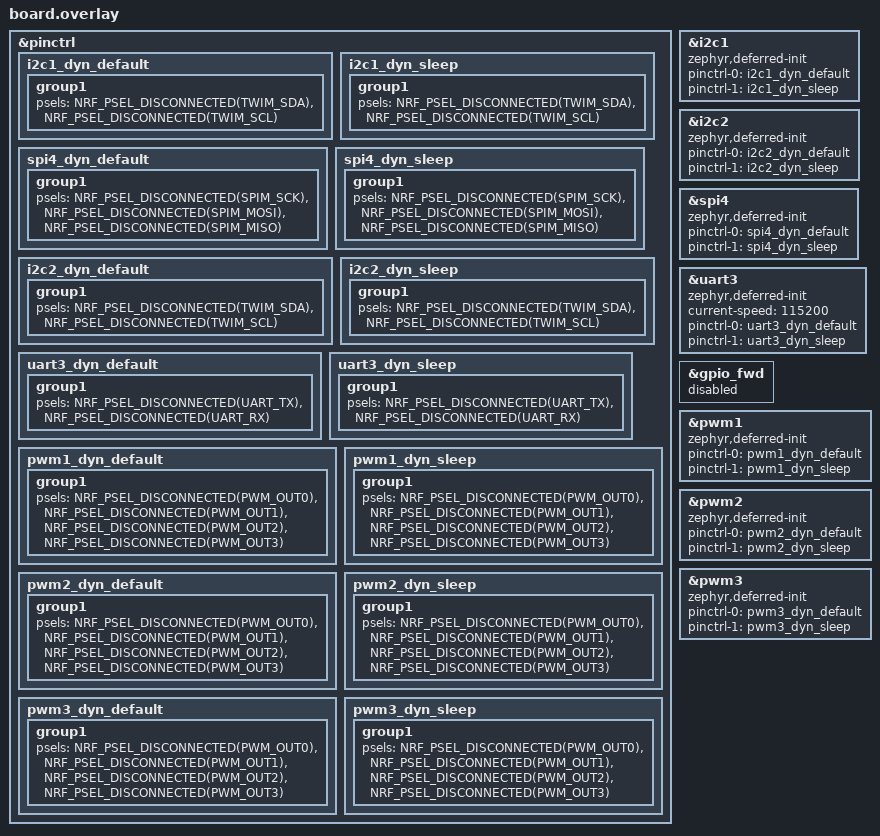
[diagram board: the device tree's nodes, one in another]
// TODO: restore the I2S for the Open Music Labs Audio Codec Shield. The fixed
// i2s0 that was here used the Arduino SPI pins (D10-D13), so board.SPI() could
// not use them, and audiobusio.I2SOut can't be routed dynamically yet.

// Enable free serial peripheral instances so CircuitPython can mux them to
// arbitrary pins at runtime. Each instance is enabled in one mode because the
// i2c/spi/uart nodes of an instance are the same peripheral (enforced by
// zephyr/soc/nordic/validate_enabled_instances.c). All signals are
// disconnected and the devices are marked zephyr,deferred-init so nothing is
// claimed at boot; iobroker initializes and routes a device when a busio
// object is constructed and de-initializes it on release.
//
// See "nRF serial instances" in internal-modules/iobroker/README.md for how
// the instances are shared and allocated.
//
// Instance 0 is left alone: uart0 is the console and i2c0/spi0 share that
// same peripheral, so they must not be enabled. Instance 1 is i2c1, the
// Arduino header I2C. spi4 is the upstream Arduino header SPI and the only
// SPI instance. uart1 is the upstream Arduino serial, but it is the same
// instance as i2c1, so busio.UART uses uart3.

&pinctrl {
	i2c1_dyn_default: i2c1_dyn_default {
		group1 {
			psels = <NRF_PSEL_DISCONNECTED(TWIM_SDA)>,
				<NRF_PSEL_DISCONNECTED(TWIM_SCL)>;
		};
	};

	i2c1_dyn_sleep: i2c1_dyn_sleep {
		group1 {
			psels = <NRF_PSEL_DISCONNECTED(TWIM_SDA)>,
				<NRF_PSEL_DISCONNECTED(TWIM_SCL)>;
		};
	};

	spi4_dyn_default: spi4_dyn_default {
		group1 {
			psels = <NRF_PSEL_DISCONNECTED(SPIM_SCK)>,
				<NRF_PSEL_DISCONNECTED(SPIM_MOSI)>,
				<NRF_PSEL_DISCONNECTED(SPIM_MISO)>;
		};
	};

	spi4_dyn_sleep: spi4_dyn_sleep {
		group1 {
			psels = <NRF_PSEL_DISCONNECTED(SPIM_SCK)>,
				<NRF_PSEL_DISCONNECTED(SPIM_MOSI)>,
				<NRF_PSEL_DISCONNECTED(SPIM_MISO)>;
		};
	};

	i2c2_dyn_default: i2c2_dyn_default {
		group1 {
			psels = <NRF_PSEL_DISCONNECTED(TWIM_SDA)>,
				<NRF_PSEL_DISCONNECTED(TWIM_SCL)>;
		};
	};

	i2c2_dyn_sleep: i2c2_dyn_sleep {
		group1 {
			psels = <NRF_PSEL_DISCONNECTED(TWIM_SDA)>,
				<NRF_PSEL_DISCONNECTED(TWIM_SCL)>;
		};
	};

	uart3_dyn_default: uart3_dyn_default {
		group1 {
			psels = <NRF_PSEL_DISCONNECTED(UART_TX)>,
				<NRF_PSEL_DISCONNECTED(UART_RX)>;
		};
	};

	uart3_dyn_sleep: uart3_dyn_sleep {
		group1 {
			psels = <NRF_PSEL_DISCONNECTED(UART_TX)>,
				<NRF_PSEL_DISCONNECTED(UART_RX)>;
		};
	};
};

&i2c1 {
	status = "okay";
	zephyr,deferred-init;
	pinctrl-0 = <&i2c1_dyn_default>;
	pinctrl-1 = <&i2c1_dyn_sleep>;
	pinctrl-names = "default", "sleep";
};

&i2c2 {
	status = "okay";
	zephyr,deferred-init;
	pinctrl-0 = <&i2c2_dyn_default>;
	pinctrl-1 = <&i2c2_dyn_sleep>;
	pinctrl-names = "default", "sleep";
};

&spi4 {
	status = "okay";
	zephyr,deferred-init;
	pinctrl-0 = <&spi4_dyn_default>;
	pinctrl-1 = <&spi4_dyn_sleep>;
	pinctrl-names = "default", "sleep";
};

&uart3 {
	status = "okay";
	zephyr,deferred-init;
	current-speed = <115200>;
	pinctrl-0 = <&uart3_dyn_default>;
	pinctrl-1 = <&uart3_dyn_sleep>;
	pinctrl-names = "default", "sleep";
};

// The upstream board forwards the Arduino D0/D1 pins (P1.00/P1.01) and
// P0.10/P0.11 to the network core for its UART console, so the application
// core could not use them. Keep them on the application core, for
// board.UART() on TX/RX (D1/D0).
&gpio_fwd {
	status = "disabled";
};

// PWM instances 1-3, same scheme: all four outputs disconnected and deferred
// init, so iobroker can hand an instance to neopixel_write and pwmio and
// route its outputs at runtime. Instance 0 is left as the board defines it:
// enabled with fixed pins for the PWM LED. nRF5340 has no power-domain pin
// restrictions, so any instance can drive any pad.

&pinctrl {
	pwm1_dyn_default: pwm1_dyn_default {
		group1 {
			psels = <NRF_PSEL_DISCONNECTED(PWM_OUT0)>,
				<NRF_PSEL_DISCONNECTED(PWM_OUT1)>,
				<NRF_PSEL_DISCONNECTED(PWM_OUT2)>,
				<NRF_PSEL_DISCONNECTED(PWM_OUT3)>;
		};
	};

	pwm1_dyn_sleep: pwm1_dyn_sleep {
		group1 {
			psels = <NRF_PSEL_DISCONNECTED(PWM_OUT0)>,
				<NRF_PSEL_DISCONNECTED(PWM_OUT1)>,
				<NRF_PSEL_DISCONNECTED(PWM_OUT2)>,
				<NRF_PSEL_DISCONNECTED(PWM_OUT3)>;
		};
	};

	pwm2_dyn_default: pwm2_dyn_default {
		group1 {
			psels = <NRF_PSEL_DISCONNECTED(PWM_OUT0)>,
				<NRF_PSEL_DISCONNECTED(PWM_OUT1)>,
				<NRF_PSEL_DISCONNECTED(PWM_OUT2)>,
				<NRF_PSEL_DISCONNECTED(PWM_OUT3)>;
		};
	};

	pwm2_dyn_sleep: pwm2_dyn_sleep {
		group1 {
			psels = <NRF_PSEL_DISCONNECTED(PWM_OUT0)>,
				<NRF_PSEL_DISCONNECTED(PWM_OUT1)>,
				<NRF_PSEL_DISCONNECTED(PWM_OUT2)>,
				<NRF_PSEL_DISCONNECTED(PWM_OUT3)>;
		};
	};

	pwm3_dyn_default: pwm3_dyn_default {
		group1 {
			psels = <NRF_PSEL_DISCONNECTED(PWM_OUT0)>,
				<NRF_PSEL_DISCONNECTED(PWM_OUT1)>,
				<NRF_PSEL_DISCONNECTED(PWM_OUT2)>,
				<NRF_PSEL_DISCONNECTED(PWM_OUT3)>;
		};
	};

	pwm3_dyn_sleep: pwm3_dyn_sleep {
		group1 {
			psels = <NRF_PSEL_DISCONNECTED(PWM_OUT0)>,
				<NRF_PSEL_DISCONNECTED(PWM_OUT1)>,
				<NRF_PSEL_DISCONNECTED(PWM_OUT2)>,
				<NRF_PSEL_DISCONNECTED(PWM_OUT3)>;
		};
	};
};

&pwm1 {
	status = "okay";
	zephyr,deferred-init;
	pinctrl-0 = <&pwm1_dyn_default>;
	pinctrl-1 = <&pwm1_dyn_sleep>;
	pinctrl-names = "default", "sleep";
};

&pwm2 {
	status = "okay";
	zephyr,deferred-init;
	pinctrl-0 = <&pwm2_dyn_default>;
	pinctrl-1 = <&pwm2_dyn_sleep>;
	pinctrl-names = "default", "sleep";
};

&pwm3 {
	status = "okay";
	zephyr,deferred-init;
	pinctrl-0 = <&pwm3_dyn_default>;
	pinctrl-1 = <&pwm3_dyn_sleep>;
	pinctrl-names = "default", "sleep";
};

#include "../../../app.overlay"
